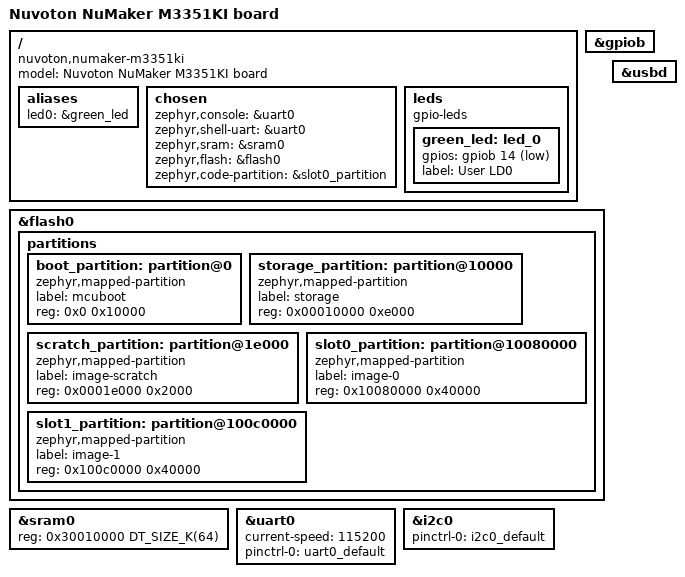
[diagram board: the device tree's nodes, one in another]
/*
 * SPDX-FileCopyrightText: Copyright (c) 2026 Nuvoton Technology Corporation
 * SPDX-License-Identifier: Apache-2.0
 */

#define NVT_DT_TZ_NSPE 1

/dts-v1/;

#include <nuvoton/m3351kjc.dtsi>
#include "numaker_m3351ki-pinctrl.dtsi"
#include <zephyr/dt-bindings/input/input-event-codes.h>

/ {
	model = "Nuvoton NuMaker M3351KI board";
	compatible = "nuvoton,numaker-m3351ki";

	aliases {
		led0 = &green_led;
	};

	chosen {
		zephyr,console = &uart0;
		zephyr,shell-uart = &uart0;
		zephyr,sram = &sram0;
		zephyr,flash = &flash0;
		zephyr,code-partition = &slot0_partition;
	};

	leds {
		compatible = "gpio-leds";

		green_led: led_0 {
			gpios = <&gpiob 14 GPIO_ACTIVE_LOW>;
			label = "User LD0";
		};
	};
};

&gpiob {
	status = "okay";
};

&flash0 {
	partitions {
		ranges;
		#address-cells = <1>;
		#size-cells = <1>;

		boot_partition: partition@0 {
			compatible = "zephyr,mapped-partition";
			label = "mcuboot";
			reg = <0x0 0x10000>;
		};

		storage_partition: partition@10000 {
			compatible = "zephyr,mapped-partition";
			label = "storage";
			reg = <0x00010000 0xe000>;
		};

		scratch_partition: partition@1e000 {
			compatible = "zephyr,mapped-partition";
			label = "image-scratch";
			reg = <0x0001e000 0x2000>;
		};

		slot0_partition: partition@10080000 {
			compatible = "zephyr,mapped-partition";
			label = "image-0";
			reg = <0x10080000 0x40000>;
		};

		slot1_partition: partition@100c0000 {
			compatible = "zephyr,mapped-partition";
			label = "image-1";
			reg = <0x100c0000 0x40000>;
		};
	};
};

&sram0 {
	reg = <0x30010000 DT_SIZE_K(64)>;
};

&uart0 {
	current-speed = <115200>;
	pinctrl-0 = <&uart0_default>;
	pinctrl-names = "default";
	status = "okay";
};

arduino_i2c: &i2c0 {
	pinctrl-0 = <&i2c0_default>;
	pinctrl-names = "default";
	status = "okay";
};

zephyr_udc0: &usbd {
	/*
	 * Clock source defaults to HIRC, which runs at required 48MHz.
	 * Pinctrl is unneeded because pins are dedicated.
	 */
	status = "okay";
};
